# STM32MP25_CM33 register map
File version: 1.3
CPU: CM33 r0p1, little endian, MPU, FPU, vendor SysTick, 8 interrupt priority bits
Registers are 32-bit, read-write, reset 0x0 unless marked. A register's access mark holds for its fields unless they carry their own. Offsets are from the block's base; [hi:lo] are bit positions; lines under a group give offsets from that group; {n}, {i} and the like mark numbered series; 'fields as' and 'values as' point back to an identical list.

## DDRCTRL — DDRCTRL register block
Base 0x48040000
Same registers: DDRCTRL_S 0x58040000
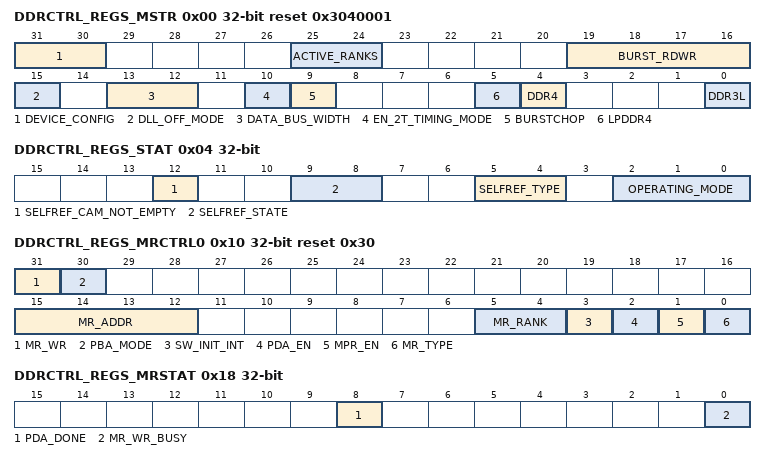
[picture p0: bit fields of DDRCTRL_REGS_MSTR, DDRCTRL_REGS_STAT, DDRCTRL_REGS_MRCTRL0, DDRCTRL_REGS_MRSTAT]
0x00 DDRCTRL_REGS_MSTR reset 0x3040001 — DDRCTRL master0 register
  [31:30] DEVICE_CONFIG — Device configuration
    0=x4 device; 1=x8 device; 2=x16 device; 3=x32 device
  [25:24] ACTIVE_RANKS — Only present for multi-rank configurations
    1=One rank; 0=Unpopulated; 3=Two ranks
  [19:16] BURST_RDWR — SDRAM burst length
    2=Burst length of 4; 4=Burst length of 8; 8=Burst length of 16 (only supported for LPDDR4)
  [15] DLL_OFF_MODE — Note: Programming mode: Quasi-dynamic Group 2.
    1=When the DDRCTRL and DRAM has to be put in DLL-off mode for low frequency operation; 0=To put DDRCTRL and DRAM in DLL-on mode for normal frequency operation
  [13:12] DATA_BUS_WIDTH — Proportion of DQ bus width that is used by the SDRAM
    0=32 bits; 1=16 bits; 2=8 bits (supported for DDR3L half populated)
  [10] EN_2T_TIMING_MODE — In 2T timing, all command signals (except chip select) are held for two clocks on the SDRAM bus.
    0=DDRCTRL uses 1T timing; 1=DDRCTRL uses 2T timing
  [9] BURSTCHOP — Burst chop (BC4 or 8 on-the-fly) enable in DDR3L/DDR4
  [5] LPDDR4 — Selects LPDDR4 SDRAM
    1=LPDDR4 SDRAM device; 0=Non-LPDDR4 device
  [4] DDR4 — Selects DDR4 SDRAM
    1=DDR4 SDRAM device; 0=Non-DDR4 device
  [0] DDR3L — Selects DDR3L SDRAM
    1=DDR3L SDRAM device; 0=Non-DDR3L SDRAM device
0x04 DDRCTRL_REGS_STAT ro — DDRCTRL operating mode status register
  [12] SELFREF_CAM_NOT_EMPTY — Self-refresh (SR) with CAMs not empty
  [9:8] SELFREF_STATE — SR or SRPD (SR power-down) for LPDDR4
    0=SDRAM not in SR; 1=SR 1; 2=SRPD; 3=SR 2
  [5:4] SELFREF_TYPE — Flags if SR (except LPDDR4), or SRPD (LPDDR4) is entered, and if it is under automatic SR control only or not
    0=SDRAM is not in SR (except LPDDR4) or SRPD (LPDDR4); 3=SDRAM is in SR (except LPDDR4) or SRPD(LPDDR4), which was caused by automatic SR only; 2=SDRAM is in SR (except LPDDR4) or SRPD (LPDDR4), which was not caused solely under automatic SR control; 1=SDRAM is in SR, which is caused by PHY master request
  [2:0] OPERATING_MODE — DDR3L design:
    0=Init; 1=Normal; 2=PDN; 3=SR/SRSRPD
0x10 DDRCTRL_REGS_MRCTRL0 reset 0x30 — DDRCTRL mode read/write control 0 register
  [31] MR_WR — Mode register (MR) read or write
  [30] PBA_MODE — PBA access execution
    0=PDA; 1=PBA
  [15:12] MR_ADDR ro — MR address to be written to
    {v}=MR{v} (v=0..7)
  [5:4] MR_RANK — Rank accessed by MR_WR in this register
    1=Select rank 0 only; 2=Select rank 1 only; 3=Select ranks 0 and 1
  [3] SW_INIT_INT — Software intervention enable
    0=Software intervention not allowed; 1=Software intervention allowed
  [2] PDA_EN — Mode register operation is MRS in PDA mode or not
    0=MRS; 1=MRS in PDA
  [1] MPR_EN — Mode register operation is MRS or WR/RD for MPR (only supported for DDR4)
    0=MRS; 1=WR/RD for MPR
  [0] MR_TYPE — Mode register operation is read or write (only for LPDDR4/DDR4)
    0=Write; 1=Read
0x14 DDRCTRL_REGS_MRCTRL1 — DDRCTRL mode read/write control 1 register
  [17:0] MR_DATA — Mode register write data for all non-LPDDR4 modes
0x18 DDRCTRL_REGS_MRSTAT ro — DDRCTRL mode register read/write status register
  [8] PDA_DONE — Initiate an MR write operation in PDA/PBA mode only if this bit is low
    0=Mode register write operation related to PDA/PBA is in progress or has not started yet; 1=Mode register write operation related to PDA/PBA has competed
  [0] MR_WR_BUSY — Initiate an MR write operation only if this bit is low
    0=The device can initiate a mode register write operation; 1=Mode register write operation is in progress
0x1C DDRCTRL_REGS_MRCTRL2 — DDRCTRL mode register read/write control 2 register
  [31:0] MR_DEVICE_SEL — Device selection during the MRS that happens in PDA mode
    1=MRS command must be applied to that device; 0=MRS commands must be skipped for that device
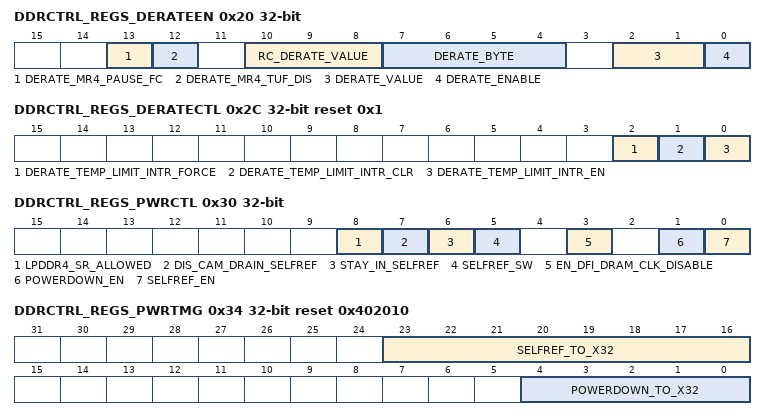
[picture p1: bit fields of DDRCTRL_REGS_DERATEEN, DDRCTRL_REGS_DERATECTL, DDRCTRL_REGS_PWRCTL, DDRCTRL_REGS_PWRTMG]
0x20 DDRCTRL_REGS_DERATEEN — DDRCTRL temperature derate enable register
  [13] DERATE_MR4_PAUSE_FC — Pauses MR4 reads
  [12] DERATE_MR4_TUF_DIS — Disables use of MR4 TUF flag (MR4[7])
    0=Use MR4 TUF flag (MR4[7]); 1=Do not use MR4 TUF Flag (MR4[7])
  [10:8] RC_DERATE_VALUE — Derate value of tless thansub>RCless than/sub> for LPDDR4
    {v}=Derating uses +{v+1} (v=0..7)
  [7:4] DERATE_BYTE — MRR data used for derating
  [2:1] DERATE_VALUE
    {v}=Derating uses +{v+1} (v=0..3)
  [0] DERATE_ENABLE — Enables derating
    0=Timing parameter derating is disabled; 1=Timing parameter derating is enabled using MR4 read value
0x24 DDRCTRL_REGS_DERATEINT reset 0x800000 — DDRCTRL temperature derate interval register
  [31:0] MR4_READ_INTERVAL — Interval between two MR4 reads
0x2C DDRCTRL_REGS_DERATECTL reset 0x1 — DDRCTRL temperature derate control register
  [2] DERATE_TEMP_LIMIT_INTR_FORCE — Interrupt force bit for DERATE_TEMP_LIMIT_INTR
  [1] DERATE_TEMP_LIMIT_INTR_CLR — Interrupt clear bit for DERATE_TEMP_LIMIT_INTR
  [0] DERATE_TEMP_LIMIT_INTR_EN — Interrupt enable bit for DERATE_TEMP_LIMIT_INTR
    1=Enabled; 0=Disabled
0x30 DDRCTRL_REGS_PWRCTL — DDRCTRL low-power control register
  [8] LPDDR4_SR_ALLOWED — Transition from SRPD to SR, and back to SRPD allowed
    0=SRPD -> SR -> SRPD not allowed; 1=SRPD -> SR -> SRPD allowed
  [7] DIS_CAM_DRAIN_SELFREF — Skipping CAM draining allowed when entering SR
    0=CAMs must be empty before entering SR; 1=CAMs are not empty before entering SR (not supported)
  [6] STAY_IN_SELFREF — SR state transition
    1=Transition from SR not allowed; 0=Transition from SR allowed
  [5] SELFREF_SW — SR state entry
    1=Software entry to SR; 0=Software exit from SR
  [3] EN_DFI_DRAM_CLK_DISABLE — dfi_dram_clk_disable enable
    0=dfi_dram_clk_disable is never asserted; 1=Assertion of dfi_dram_clk_disable as follows: In DDR3L and DDR4, can only be asserted in SR
  [1] POWERDOWN_EN — PDN enable
  [0] SELFREF_EN — SDRAM into SR enable
0x34 DDRCTRL_REGS_PWRTMG reset 0x402010 — DDRCTRL low-power timing register
  [23:16] SELFREF_TO_X32 — Maximum idle clocks before SR
  [4:0] POWERDOWN_TO_X32 — Maximum idle clocks before PDN
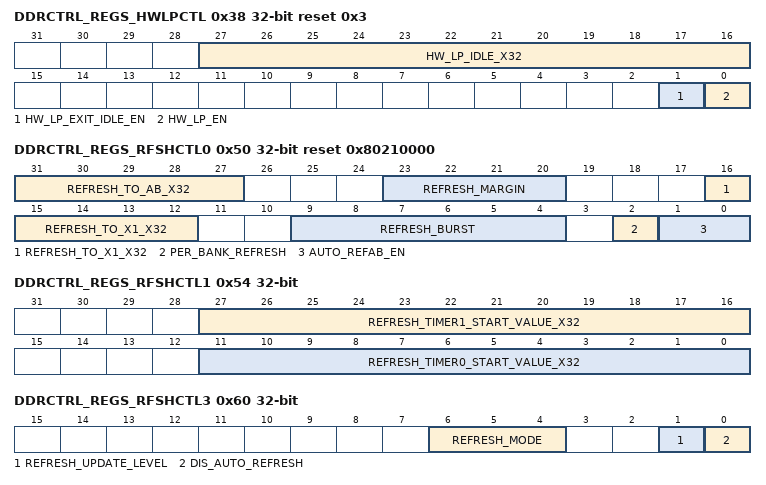
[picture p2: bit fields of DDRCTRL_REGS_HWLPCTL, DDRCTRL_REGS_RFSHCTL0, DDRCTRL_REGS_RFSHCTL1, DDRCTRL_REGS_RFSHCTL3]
0x38 DDRCTRL_REGS_HWLPCTL reset 0x3 — DDRCTRL hardware low-power control register
  [27:16] HW_LP_IDLE_X32 — Hardware idle period
  [1] HW_LP_EXIT_IDLE_EN — CACTIVE_IN_DDRC pin enable
  [0] HW_LP_EN — Hardware low-power interface enable
0x50 DDRCTRL_REGS_RFSHCTL0 reset 0x80210000 — DDRCTRL refresh control 0 register
  [31:27] REFRESH_TO_AB_X32 — When the DDRCTRL switches automatically from per-bank to all-bank refresh (if enabled by AUTO_REFAB_EN[1:0]), it will use this register to determine when to perform speculative all-bank refreshes.
  [23:20] REFRESH_MARGIN — DFI clock cycles before the critical refresh or page timer expires
  [16:12] REFRESH_TO_X1_X32 — If the refresh timer (tless thansub>RFCnomless than/sub>, also known as tless thansub>REFIless than/sub>) has expired at least once, a speculative refresh can be performed.
  [9:4] REFRESH_BURST — This bit field + 1 is the number of refresh timeouts that can be accumulated before traffic is blocked, and refreshes are forced to execute.
    0=Single refresh; 1=Burst-of-2 refresh; 7=Burst-of-8 refresh
  [2] PER_BANK_REFRESH — Per bank refresh allows traffic to flow to other banks (supported by all LPDDR4 devices).
    1=Per bank refresh; 0=All bank refresh
  [1:0] AUTO_REFAB_EN — Enables automatic switching from per-bank to all-bank refresh when the derated refresh period is small.
    0=Disable automatic switching; 1=Enable automatic switching when the derated refresh period is tless thansub>REFIless than/sub>/2 or lower; 2=Enable automatic switching when the derated refresh period is tless thansub>REFIless than/sub>/4
0x54 DDRCTRL_REGS_RFSHCTL1 — DDRCTRL refresh control 1 register
  [27:16] REFRESH_TIMER1_START_VALUE_X32 — Refresh timer start for rank 1 (only present in multirank configurations)
  [11:0] REFRESH_TIMER0_START_VALUE_X32 — Refresh timer start for rank 0 (only present in multirank configurations)
0x60 DDRCTRL_REGS_RFSHCTL3 — DDRCTRL refresh control 3 register
  [6:4] REFRESH_MODE — Fine granularity refresh mode
    0=Fixed 1x (normal mode); 1=Fixed 2x; 2=Fixed 4x; 5=Enable on-the-fly 2x (not supported); 6=Enable on-the-fly 4x (not supported)
  [1] REFRESH_UPDATE_LEVEL — Refresh register update
  [0] DIS_AUTO_REFRESH — Auto-refresh disable
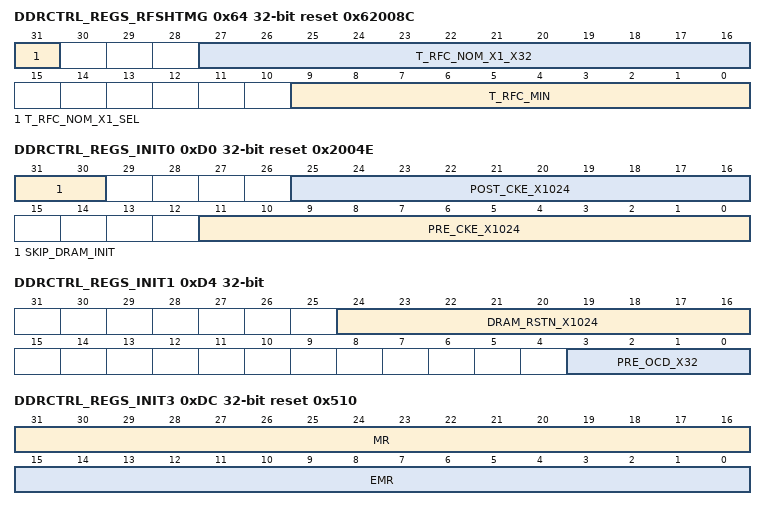
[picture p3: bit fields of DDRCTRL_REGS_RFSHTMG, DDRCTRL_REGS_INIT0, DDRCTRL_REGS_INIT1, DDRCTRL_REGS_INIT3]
0x64 DDRCTRL_REGS_RFSHTMG reset 0x62008C — DDRCTRL refresh timing register
  [31] T_RFC_NOM_X1_SEL — This bit specifies whether values of T_RFC_NOM_X1_X32 in this register and REFRESH_TO_X1_X32 in DDRCTRL_REGS_RFSHCTL0 are x1 or x32.
    0=x32 register values; 1=x1 register values
  [27:16] T_RFC_NOM_X1_X32 — Average time interval between refreshes per rank
  [9:0] T_RFC_MIN — tless thansub>RFCminless than/sub>, minimum time from refresh to refresh or activate
0x68 DDRCTRL_REGS_RFSHTMG1 reset 0x8C0000 — DDRCTRL refresh timing1 register
  [23:16] T_PBR2PBR — tless thansub>pbR2pbRless than/sub> for LPDDR4
0xD0 DDRCTRL_REGS_INIT0 reset 0x2004E — DDRCTRL SDRAM initialization 0 register
  [31:30] SKIP_DRAM_INIT — SDRAM initialization routine
    0=The SDRAM initialization routine is run after power-up; 1=The SDRAM initialization routine is skipped after power-up; 3=The SDRAM initialization routine is skipped after power-up
  [25:16] POST_CKE_X1024 — Number of cycles to wait after driving CKE high to start the SDRAM initialization sequence
  [11:0] PRE_CKE_X1024 — Number of cycles to wait after reset before driving CKE high to start the SDRAM initialization sequence
0xD4 DDRCTRL_REGS_INIT1 — DDRCTRL SDRAM initialization 1 register
  [24:16] DRAM_RSTN_X1024 — Number of cycles to assert SDRAM reset signal during
  [3:0] PRE_OCD_X32 — Wait period before driving the OCD complete command to SDRAM
0xDC DDRCTRL_REGS_INIT3 reset 0x510 — DDRCTRL SDRAM initialization 3 register
  [31:16] MR — DDR3L/DDR4: Value loaded into MR0 register
  [15:0] EMR — DDR3L/DDR4: Value to write to MR1 register (set bit 7 to 0)
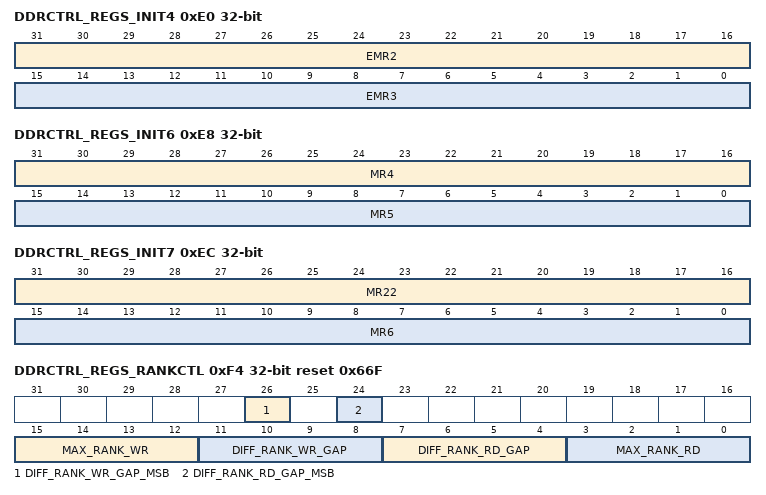
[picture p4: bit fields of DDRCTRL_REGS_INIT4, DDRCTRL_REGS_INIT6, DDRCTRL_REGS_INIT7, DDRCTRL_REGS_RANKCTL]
0xE0 DDRCTRL_REGS_INIT4 — DDRCTRL SDRAM initialization 4 register
  [31:16] EMR2 — DDR3L/DDR4: Value to write to MR2 register
  [15:0] EMR3 — DDR3L/DDR4: Value to write to MR3 register
0xE4 DDRCTRL_REGS_INIT5 reset 0x100004 — DDRCTRL SDRAM initialization 5 register
  [23:16] DEV_ZQINIT_X32 — tless thansub>ZQINITless than/sub>, ZQ initial calibration
0xE8 DDRCTRL_REGS_INIT6 — DDRCTRL SDRAM initialization 6 register
  [31:16] MR4 — DDR4: Value to be loaded into SDRAM MR4 registers
  [15:0] MR5 — DDR4: Value to be loaded into SDRAM MR5 registers
0xEC DDRCTRL_REGS_INIT7 — DDRCTRL SDRAM initialization 7 register
  [31:16] MR22 — LPDDR4: Value to be loaded into SDRAM MR22 registers
  [15:0] MR6 — DDR4: Value to be loaded into SDRAM MR6 registers
0xF4 DDRCTRL_REGS_RANKCTL reset 0x66F — DDRCTRL rank control register
  [26] DIFF_RANK_WR_GAP_MSB — 1-bit extension to be used when DIFF_RANK_WR_GAP in this register needs to be set
  [24] DIFF_RANK_RD_GAP_MSB — 1-bit extension to be used when DIFF_RANK_RD_GAP in this register needs to be set
  [15:12] MAX_RANK_WR — Maximum number of writes that can be scheduled consecutively
  [11:8] DIFF_RANK_WR_GAP — Number of clocks of gap in data responses when performing consecutive writes to different ranks (only present for multirank configurations)
  [7:4] DIFF_RANK_RD_GAP — Number of clocks of gap in data responses when performing consecutive reads to different ranks (only present for multi-rank configurations)
  [3:0] MAX_RANK_RD — Maximum number of reads that can be scheduled consecutively
0xF8 DDRCTRL_REGS_RANKCTL1 reset 0x8 — Rank control 1 register
  [5:0] WR2RD_DR — Minimum time from write command to read command on different physical ranks.
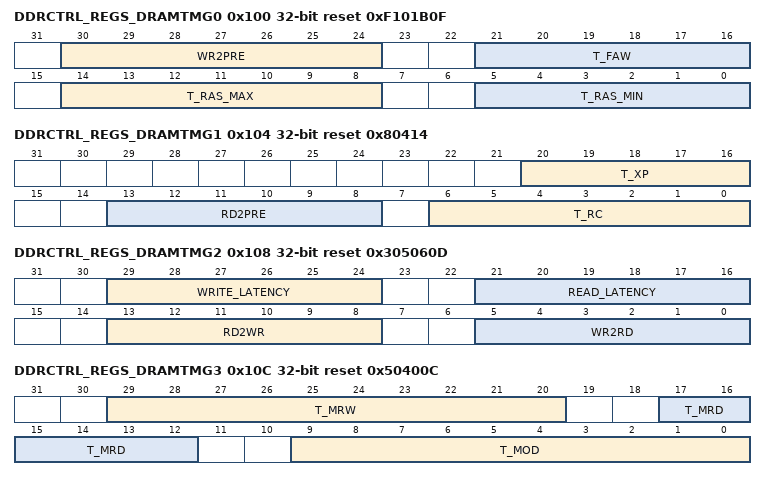
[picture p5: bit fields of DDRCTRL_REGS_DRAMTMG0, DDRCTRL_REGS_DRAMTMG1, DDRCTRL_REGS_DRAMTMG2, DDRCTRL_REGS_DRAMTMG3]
0x100 DDRCTRL_REGS_DRAMTMG0 reset 0xF101B0F — DDRCTRL SDRAM timing 0 register
  [30:24] WR2PRE — Minimum time between write and precharge to same bank
  [21:16] T_FAW — tless thansub>FAWless than/sub>, valid only when 8 or more banks (or banks x bank groups) are present
  [14:8] T_RAS_MAX — tless thansub>RASmaxless than/sub>, max time between activate and precharge to same bank
  [5:0] T_RAS_MIN — tless thansub>RASminless than/sub>, minimum time between activate and precharge to same bank
0x104 DDRCTRL_REGS_DRAMTMG1 reset 0x80414 — DDRCTRL SDRAM timing 1 register
  [20:16] T_XP — tless thansub>XPless than/sub>, minimum time after PDN exit to any operation
  [13:8] RD2PRE — tless thansub>RTPless than/sub>, minimum time from read to precharge of same bank
  [6:0] T_RC — tless thansub>RCless than/sub>, minimum time between activates to same bank
0x108 DDRCTRL_REGS_DRAMTMG2 reset 0x305060D — DDRCTRL SDRAM timing 2 register
  [29:24] WRITE_LATENCY — Time from write command to write data on SDRAM interface
  [21:16] READ_LATENCY — Time from read command to read data on SDRAM interface
  [13:8] RD2WR — Minimum time from read command to write command
  [5:0] WR2RD — In DDR4, minimum time from write command to read command for same bank group.
0x10C DDRCTRL_REGS_DRAMTMG3 reset 0x50400C — DDRCTRL SDRAM timing 3 register
  [29:20] T_MRW — Time to wait after a mode register write or read (MRW or MRR)
  [17:12] T_MRD — tless thansub>MRDless than/sub>, number of cycles to wait after a mode register write or read
  [9:0] T_MOD — tless thansub>MODless than/sub>, number of cycles between load mode command and following non-load mode command (only in DDR3L and DDR4)
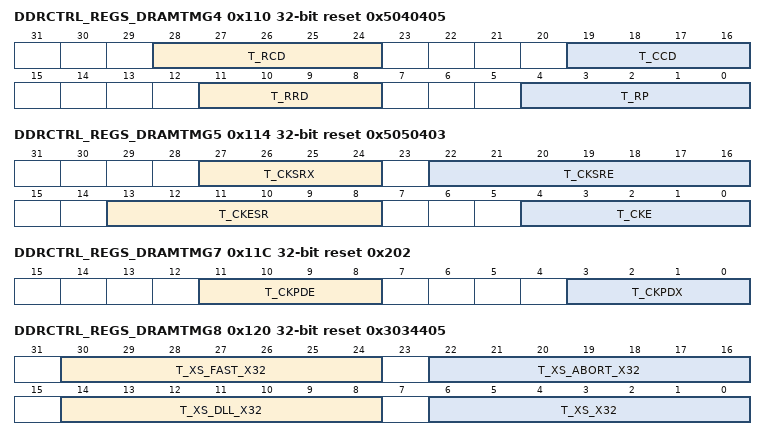
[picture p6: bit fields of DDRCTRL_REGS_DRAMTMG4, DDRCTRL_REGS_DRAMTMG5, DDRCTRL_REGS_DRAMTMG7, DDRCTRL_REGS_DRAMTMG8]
0x110 DDRCTRL_REGS_DRAMTMG4 reset 0x5040405 — DDRCTRL SDRAM timing 4 register
  [28:24] T_RCD — tless thansub>RCDless than/sub> - tless thansub>ALless than/sub>, minimum time from activate to read or write command to same bank
  [19:16] T_CCD — For DDR4, tless thansub>CCD_Lless than/sub>, minimum time between two reads or two writes for same bank group.
  [11:8] T_RRD — For DDR4, tless thansub>RRD_Lless than/sub>, minimum time between activates from bank a to bank b for same bank.
  [4:0] T_RP — tless thansub>RPless than/sub>, minimum time from single-bank precharge to activate of same bank
0x114 DDRCTRL_REGS_DRAMTMG5 reset 0x5050403 — DDRCTRL SDRAM timing 5 register
  [27:24] T_CKSRX — Time before SR exit that CK is maintained as a valid clock before issuing SRX
  [22:16] T_CKSRE — Time after SR entry that CK is maintained as a valid clock
  [13:8] T_CKESR — Minimum CKE low width for SR or SRPD entry to exit timing
  [4:0] T_CKE — Minimum number of cycles of CKE high/low during PDN and SR
0x118 DDRCTRL_REGS_DRAMTMG6 reset 0x2020005 — DDRCTRL SDRAM timing 6 register
  [3:0] T_CKCSX — time before clock Stop exit that CK is maintained as a valid clock before issuing clock Stop exit
0x11C DDRCTRL_REGS_DRAMTMG7 reset 0x202 — DDRCTRL SDRAM timing 7 register
  [11:8] T_CKPDE — Time after PDN entry that CK is maintained as a valid clock
  [3:0] T_CKPDX — Time before PDN exit that CK is maintained as a valid clock
0x120 DDRCTRL_REGS_DRAMTMG8 reset 0x3034405 — DDRCTRL SDRAM timing 8 register
  [30:24] T_XS_FAST_X32 — tless thansub>XS_FASTless than/sub>, exit SR to ZQCL, ZQCS and MRS (only CL, WR, RTP mode)
  [22:16] T_XS_ABORT_X32 — tless thansub>XS_ABORTless than/sub>, exit SR to commands not requiring a locked DLL
  [14:8] T_XS_DLL_X32 — tless thansub>XSDLLless than/sub>, exit SR to commands requiring a locked DLL (only for DDR3L and DDR4 SDRAMs)
  [6:0] T_XS_X32 — tless thansub>XSless than/sub>, exit SR to commands not requiring a locked DLL (only for DDR3L and DDR4 SDRAMs)
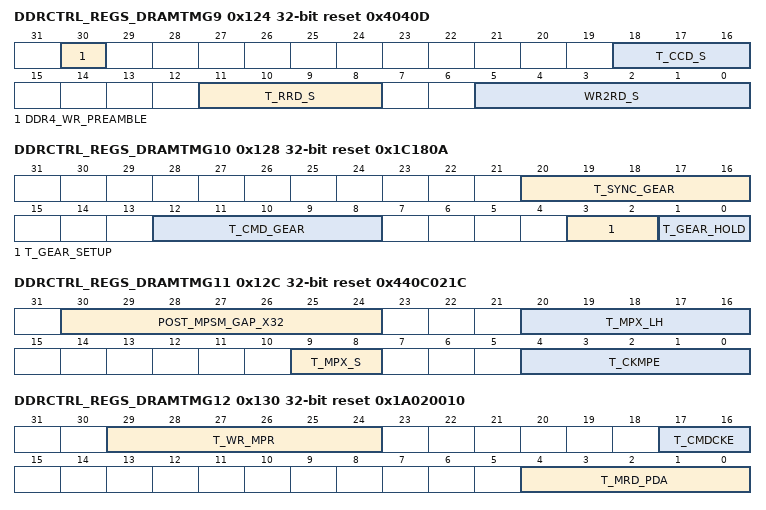
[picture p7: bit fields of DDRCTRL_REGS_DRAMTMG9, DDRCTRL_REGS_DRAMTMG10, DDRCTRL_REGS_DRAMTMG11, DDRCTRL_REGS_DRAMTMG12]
0x124 DDRCTRL_REGS_DRAMTMG9 reset 0x4040D — DDRCTRL SDRAM timing 9 register
  [30] DDR4_WR_PREAMBLE — DDR4 write preamble mode
    0=1tless thansub>CKless than/sub> preamble; 1=2tless thansub>CKless than/sub> preamble
  [18:16] T_CCD_S — tless thansub>CCD_Sless than/sub>, minimum time between two reads/writes for different bank group
  [11:8] T_RRD_S — tless thansub>RRD_Sless than/sub>, minimum time between activates for different bank group
  [5:0] WR2RD_S — Minimum time from write command to read command for different bank group
0x128 DDRCTRL_REGS_DRAMTMG10 reset 0x1C180A — DDRCTRL SDRAM timing 10 register
  [20:16] T_SYNC_GEAR — Time between MRS command and the sync pulse time
  [12:8] T_CMD_GEAR — sync pulse to first valid command
  [3:2] T_GEAR_SETUP — Geardown setup time
  [1:0] T_GEAR_HOLD — Geardown hold time
0x12C DDRCTRL_REGS_DRAMTMG11 reset 0x440C021C — DDRCTRL SDRAM timing 11 register
  [30:24] POST_MPSM_GAP_X32 — tless thansub>XMPDLLless than/sub>, minimum exit MPSM to commands requiring
  [20:16] T_MPX_LH — tless thansub>MPX_LHless than/sub>, minimum CS_n low hold time to CKE rising edge
  [9:8] T_MPX_S — tless thansub>MPX_Sless than/sub>, minimum time CS setup time to CKE
  [4:0] T_CKMPE — tless thansub>CKMPEless than/sub>, minimum valid clock requirement after MPSM entry
0x130 DDRCTRL_REGS_DRAMTMG12 reset 0x1A020010 — DDRCTRL SDRAM timing 12 register
  [29:24] T_WR_MPR — Cycles between MPR write and other commands (DDR4 only)
  [17:16] T_CMDCKE — tless thansub>CMDCKEless than/sub>, delay from valid command to CKE input low
  [4:0] T_MRD_PDA — tless thansub>MRD_PDAless than/sub>, cycle time of mode register set command in PDA mode
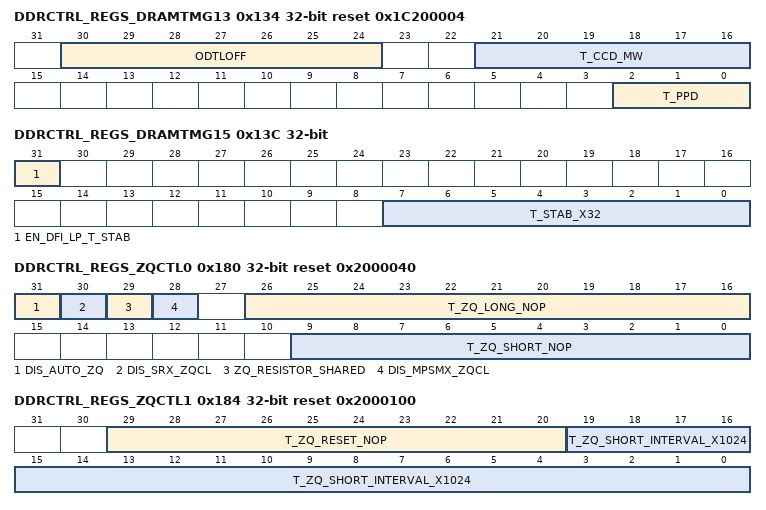
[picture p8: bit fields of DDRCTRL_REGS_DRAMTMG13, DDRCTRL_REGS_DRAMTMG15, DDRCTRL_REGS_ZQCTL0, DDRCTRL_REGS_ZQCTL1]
0x134 DDRCTRL_REGS_DRAMTMG13 reset 0x1C200004 — DDRCTRL SDRAM timing 13 register
  [30:24] ODTLOFF — ODTLoff, latency from CAS-2 command to ODToff reference (only LPDDR4)
  [21:16] T_CCD_MW — tless thansub>CCDMWless than/sub>, minimum time from write or masked write to masked write command for same bank (only LPDDR4)
  [2:0] T_PPD — tless thansub>PPDless than/sub>, minimum time from precharge to precharge command (only LPDDR4)
0x138 DDRCTRL_REGS_DRAMTMG14 reset 0xA0 — DDRCTRL SDRAM timing 14 register
  [11:0] T_XSR — tless thansub>XSRless than/sub>, exit SR time to any command (only LPDDR4)
0x13C DDRCTRL_REGS_DRAMTMG15 — DDRCTRL SDRAM timing 15 register
  [31] EN_DFI_LP_T_STAB — Note: Programming mode: Quasi-dynamic Group 2, Group 4.
    1=Enable using tless thansub>STABless than/sub> when exiting DFI LP; 0=Disable using tless thansub>STABless than/sub> when exiting DFI LP
  [7:0] T_STAB_X32 — tless thansub>STABless than/sub>, stabilization time
0x180 DDRCTRL_REGS_ZQCTL0 reset 0x2000040 — DDRCTRL ZQ control 0 register
  [31] DIS_AUTO_ZQ — Note: Programming mode: Dynamic.
    1=Disable DDRCTRL generation of ZQCS/MPC(ZQ calibration) command; 0=Internally generate ZQCS/MPC (ZQ calibration) commands based on T_ZQ_SHORT_INTERVAL_X1024 in DDRCTRL_REGS_ZQCTL1
  [30] DIS_SRX_ZQCL — Note: Programming mode: Quasi-dynamic Group 2, Group 4.
    1=Disable issuing a ZQCL/MPC(ZQ calibration) command at SR or SRPD exit; 0=Enable issuing a ZQCL/MPC(ZQ calibration) command at SR or SRPD exit
  [29] ZQ_RESISTOR_SHARED — ZQinit/ZQCL/ZQCS/MPC(ZQ calibration) commands are sent to one rank at a time with tless thansub>ZQinitless than/sub>, tless thansub>ZQCLless than/sub>, tless thansub>ZQCSless than/sub>, tless thansub>ZQCALless than/sub>, and tless thansub>ZQLATless than/sub> met between commands (so that commands to different ranks do not overlap).
    1=Denotes that ZQ resistor is shared between ranks; 0=ZQ resistor is not shared
  [28] DIS_MPSMX_ZQCL — Only for DDR4
    1=Disable issuing a ZQCL command at MPS (maximum power saving) mode exit; 0=Enable issuing a ZQCL command at MPS mode exit
  [26:16] T_ZQ_LONG_NOP — DFI clock cycles of NOP required after ZQCL (ZQcalibration long)
  [9:0] T_ZQ_SHORT_NOP — DFI clock cycles of NOP required after ZQCS (ZQ calibration short)
0x184 DDRCTRL_REGS_ZQCTL1 reset 0x2000100 — DDRCTRL ZQ control 1 register
  [29:20] T_ZQ_RESET_NOP — tless thansub>ZQResetless than/sub>, DFI clock cycles of NOP required after ZQReset
  [19:0] T_ZQ_SHORT_INTERVAL_X1024 — Average interval to wait between automatically issuing ZQCS (ZQ calibration short) and MPC(ZQ calibration) commands
0x188 DDRCTRL_REGS_ZQCTL2 — DDRCTRL ZQ control 2 register
  [0] ZQ_RESET — ZQ Reset operation
0x18C DDRCTRL_REGS_ZQSTAT ro — DDRCTRL ZQ status register
  [0] ZQ_RESET_BUSY — ZQ Reset operation possible only if this bit is low
    0=AZQ Reset operation can be initiated; 1=A ZQ Reset operation is in progress
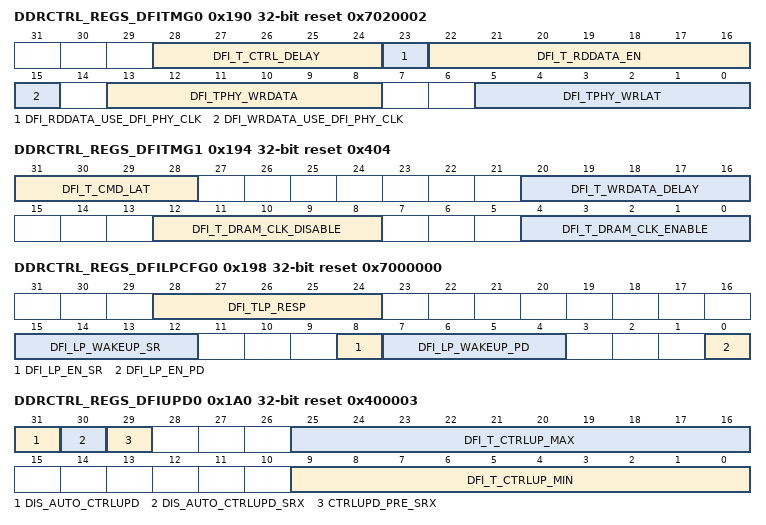
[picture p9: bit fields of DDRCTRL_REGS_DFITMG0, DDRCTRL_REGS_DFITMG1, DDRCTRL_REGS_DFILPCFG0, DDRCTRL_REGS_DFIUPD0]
0x190 DDRCTRL_REGS_DFITMG0 reset 0x7020002 — DDRCTRL DFI timing 0 register
  [28:24] DFI_T_CTRL_DELAY — DFI clock cycles after an assertion or deassertion
  [23] DFI_RDDATA_USE_DFI_PHY_CLK — dfi_rddata_en, dfi_rddata, or dfi_rddata_valid generated
    0=HDR (DFI clock) cycles; 1=SDR (DFI PHY clock) cycles
  [22:16] DFI_T_RDDATA_EN — Time from the assertion of a read command on the DFI interface
  [15] DFI_WRDATA_USE_DFI_PHY_CLK — dfi_wrdata_en, dfi_wrdata, or dfi_wrdata_mask generated
    0=HDR (DFI clock) cycles; 1=SDR (DFI PHY clock) cycles
  [13:8] DFI_TPHY_WRDATA — tless thansub>PHY_WRDATA, less than/sub>number of clock cycles between dfi_wrdata_en assertion and associated write data driven on dfi_wrdata
  [5:0] DFI_TPHY_WRLAT — tless thansub>PHY_WRLATless than/sub>, write latency
0x194 DDRCTRL_REGS_DFITMG1 reset 0x404 — DDRCTRL DFI timing 1 register
  [31:28] DFI_T_CMD_LAT — Number of DFI PHY clock cycles between when dfi_cs assertion and when the associated command is driven
  [20:16] DFI_T_WRDATA_DELAY — tless thansub>WRDATA_DELAYless than/sub>, DFI clock cycles between dfi_wrdata_en assertion, and when the corresponding write data transfer is completed on the DRAM bus
  [12:8] DFI_T_DRAM_CLK_DISABLE — DFI clock cycles from dfi_dram_clk_disable assertion on the DFI until the clock to the DRAM memory devices, at the PHY-DRAM boundary
  [4:0] DFI_T_DRAM_CLK_ENABLE — DFI clock cycles from dfi_dram_clk_disable deassertion on the DFI until the first valid rising edge of the clock to the DRAM memory devices,
0x198 DDRCTRL_REGS_DFILPCFG0 reset 0x7000000 — DDRCTRL DFI low-power configuration 0 register
  [28:24] DFI_TLP_RESP — tless thansub>LP_RESPless than/sub>, DFI clock cycles setting for DFI
  [15:12] DFI_LP_WAKEUP_SR — tless thansub>LP_WAKEUPless than/sub>, DFI clock cycles to drive on dfi_lp_wakeup signal
    0=16 cycles; 1=32 cycles; 2=64 cycles; 3=128 cycles; 4=256 cycles; 5=512 cycles; 6=1024 cycles; 7=2048 cycles; 8=4096 cycles; 9=8192 cycles; 10=16384 cycles; 11=32768 cycles; 12=65536 cycles; 13=131072 cycles; 14=262144 cycles; 15=Unlimited
  [8] DFI_LP_EN_SR — DFI low-power interface handshaking during SR entry/exit
    0=Disabled; 1=Enabled
  [7:4] DFI_LP_WAKEUP_PD — tless thansub>LP_WAKEUPless than/sub>, DFI clock cycles to drive on dfi_lp_wakeup signal when PDN is entered
    values as DFI_LP_WAKEUP_SR
  [0] DFI_LP_EN_PD — DFI low-power interface handshaking during PDN entry/exit
    0=Disabled; 1=Enabled
0x1A0 DDRCTRL_REGS_DFIUPD0 reset 0x400003 — DDRCTRL DFI update 0 register
  [31] DIS_AUTO_CTRLUPD — Note: Programming mode: Quasi-dynamic Group 3.
    1=Disable the automatic DFI_CTRLUPD_REQ generation; 0=DDRCTRL issues DFI_CTRLUPD_REQ periodically
  [30] DIS_AUTO_CTRLUPD_SRX — Note: Programming mode: Static.
    1=Disable the automatic DFI_CTRLUPD_REQ generation by the DDRCTRL at SR exit; 0=DDRCTRL issues a DFI_CTRLUPD_REQ before or after exiting SR, depending on CTRLUPD_PRE_SRX in this register
  [29] CTRLUPD_PRE_SRX — DFI_CTRLUPD_REQ requirements at SRX
    0=Send DFI_CTRLUPD_REQ after SRX; 1=Send DFI_CTRLUPD_REQ before SRX
  [25:16] DFI_T_CTRLUP_MAX — Maximum number of DFI clock cycles that
  [9:0] DFI_T_CTRLUP_MIN — Minimum number of DFI clock cycles to which
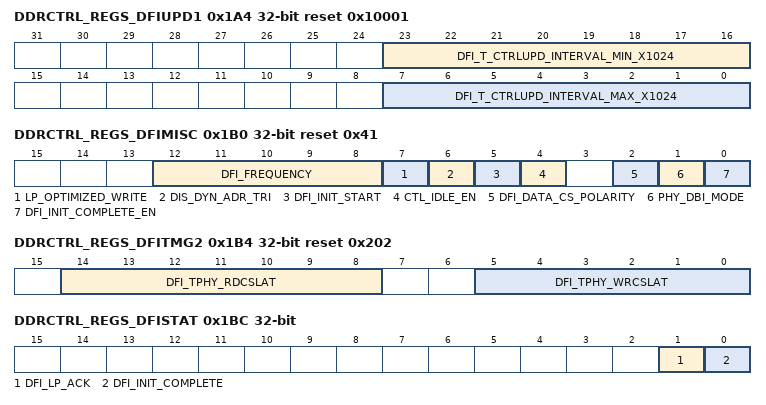
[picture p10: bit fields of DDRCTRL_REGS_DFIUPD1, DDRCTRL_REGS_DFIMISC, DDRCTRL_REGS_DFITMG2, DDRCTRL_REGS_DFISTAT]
0x1A4 DDRCTRL_REGS_DFIUPD1 reset 0x10001 — DDRCTRL DFI update 1 register
  [23:16] DFI_T_CTRLUPD_INTERVAL_MIN_X1024 — Minimum amount of time between DDRCTRL initiated DFI update requests (which is executed whenever the DDRCTRL is idle)
  [7:0] DFI_T_CTRLUPD_INTERVAL_MAX_X1024 — Maximum amount of time between DDRCTRL initiated DFI update requests
0x1A8 DDRCTRL_REGS_DFIUPD2 reset 0x80000000 — DDRCTRL DFI update 2 register
  [31] DFI_PHYUPD_EN — Enables the support for acknowledging PHY-initiated updates
    0=Disabled; 1=Enabled
0x1B0 DDRCTRL_REGS_DFIMISC reset 0x41 — DDRCTRL DFI miscellaneous control register
  [12:8] DFI_FREQUENCY — System operating frequency
  [7] LP_OPTIMIZED_WRITE — Note: Programming mode: Quasi-dynamic Group 3
    1=LPDDR4 write DQ is set to 0xF8 if masked write with enabling DBI; 0=LPDDR4 write DQ is set to 0xFF
  [6] DIS_DYN_ADR_TRI — the PHY can detect it to turn the command/address bus Hi-Z.
    1=PHY specific dynamic tristating is disabled (specific feature to some Synopsys PHYs); 0=A special IDLE command is issued on the DFI while dfi_cs is inactive state, so that
  [5] DFI_INIT_START — PHY init start request
  [4] CTL_IDLE_EN — Enables support of ctl_idle signal (non-DFI related pin specific to certain Synopsys PHYs)
  [2] DFI_DATA_CS_POLARITY — Polarity of dfi_wrdata_cs and dfi_rddata_cs signals
    0=Active low; 1=Active high
  [1] PHY_DBI_MODE — DBI implemented in DDRC or PHY
    0=DDRC implements DBI functionality; 1=PHY implements DBI functionality
  [0] DFI_INIT_COMPLETE_EN — PHY initialization complete enable
0x1B4 DDRCTRL_REGS_DFITMG2 reset 0x202 — DDRCTRL DFI timing 2 register
  [14:8] DFI_TPHY_RDCSLAT — tless thansub>PHY_RDCSLAT, less than/sub>DFI PHY clock cycles between read command sent on the DFI control interface, and associated dfi_rddata_cs signal asserted
  [5:0] DFI_TPHY_WRCSLAT — tless thansub>PHY_WRCSLATless than/sub>, DFI PHY clock cycles between write command sent on the DFI control interface, and associated dfi_wrdata_cs signal asserted.
0x1B8 DDRCTRL_REGS_DFITMG3 — DDRCTRL DFI timing 3 register
  [4:0] DFI_T_GEARDOWN_DELAY — Delay from dfi_geardown_en assertion to the time of t
0x1BC DDRCTRL_REGS_DFISTAT ro — DDRCTRL DFI status register
  [1] DFI_LP_ACK — Stores the value of dfi_lp_ack input to the controller
  [0] DFI_INIT_COMPLETE — Status flag that announces when DFI initialization is completed
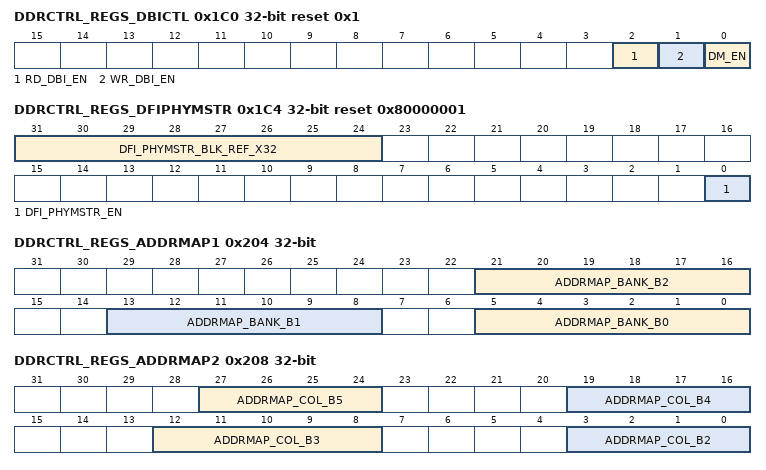
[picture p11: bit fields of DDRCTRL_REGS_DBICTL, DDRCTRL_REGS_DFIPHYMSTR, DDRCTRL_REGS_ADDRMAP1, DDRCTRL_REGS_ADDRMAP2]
0x1C0 DDRCTRL_REGS_DBICTL reset 0x1 — DDRCTRL DM/DBI control register
  [2] RD_DBI_EN — Read DBI enable signal in DDRC
    0=Read DBI disabled; 1=Read DBI enabled
  [1] WR_DBI_EN — Write DBI enable signal in DDRC
    0=Write DBI disabled; 1=Write DBI enabled
  [0] DM_EN — DM enable signal in DDRC
    0=DM disabled; 1=DM enabled
0x1C4 DDRCTRL_REGS_DFIPHYMSTR reset 0x80000001 — DDRCTRL DFI PHY master register
  [31:24] DFI_PHYMSTR_BLK_REF_X32 — Maximum number of DFI clock cycles that are needed to send pending refreshes before starting SR entry process
    0=0 DFI clock cycles (no delay); 1=32 DFI clock cycles; 255=8160 DFI clock cycles
  [0] DFI_PHYMSTR_EN — PHY master interface enable
    0=Disabled; 1=Enabled
0x200 DDRCTRL_REGS_ADDRMAP0 — DDRCTRL address map 0 register
  [4:0] ADDRMAP_CS_BIT0 — This bit field selects the HIF address bit used as rank address bit 0.
0x204 DDRCTRL_REGS_ADDRMAP1 — DDRCTRL address map 1 register
  [21:16] ADDRMAP_BANK_B2 — This bit field selects the HIF address bit used as bank address bit 2.
  [13:8] ADDRMAP_BANK_B1 — This bit field selects the HIF address bits used as bank address bit 1.
  [5:0] ADDRMAP_BANK_B0 — This bit field selects the HIF address bits used as bank address bit 0.
0x208 DDRCTRL_REGS_ADDRMAP2 — DDRCTRL address map 2 register
  [27:24] ADDRMAP_COL_B5 — Full bus width mode: selects the HIF address bit used as columnaddress bit 5.
  [19:16] ADDRMAP_COL_B4 — Full bus width mode: selects the HIF address bit used as column address bit 4.
  [12:8] ADDRMAP_COL_B3 — Full bus width mode: selects the HIF address bit used as column address bit 3.
  [3:0] ADDRMAP_COL_B2 — Full bus width mode: selects the HIF address bit used as column address bit 2.
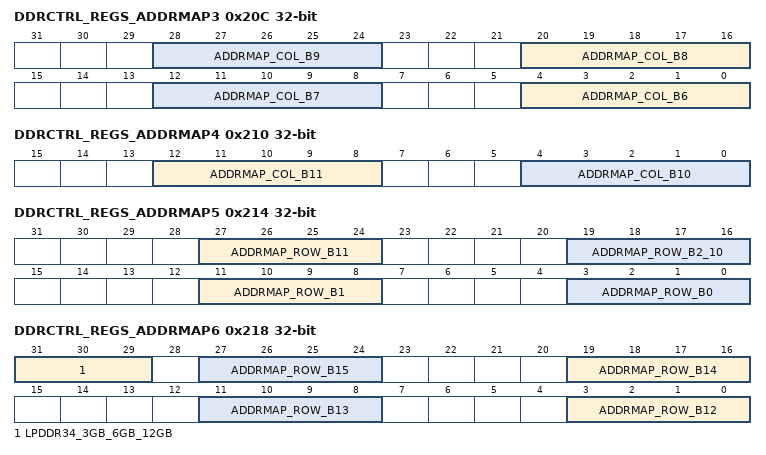
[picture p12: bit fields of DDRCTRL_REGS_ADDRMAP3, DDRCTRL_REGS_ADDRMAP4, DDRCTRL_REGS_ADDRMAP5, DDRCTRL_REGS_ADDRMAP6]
0x20C DDRCTRL_REGS_ADDRMAP3 — DDRCTRL address map 3 register
  [8n-44:8n-48] ADDRMAP_COL_B{n} (n=6..9) — Full bus width mode: selects the HIF address bit used as column address bit {n}.
0x210 DDRCTRL_REGS_ADDRMAP4 — DDRCTRL address map 4 register
  [12:8] ADDRMAP_COL_B11 — Full bus width mode: selects the HIF address bit used as column address bit 13.
  [4:0] ADDRMAP_COL_B10 — Full bus width mode: selects the HIF address bit used as column address bit 11.
0x214 DDRCTRL_REGS_ADDRMAP5 — DDRCTRL address map 5 register
  [27:24] ADDRMAP_ROW_B11 — This bit field selects the HIF address bit used as row address bit 11.
  [19:16] ADDRMAP_ROW_B2_10 — This bit field selects the HIF address bits used as row address bits 2 to 10.
  [11:8] ADDRMAP_ROW_B1 — This bit field selects the HIF address bits used as row address bit 1.
  [3:0] ADDRMAP_ROW_B0 — This bit field selects the HIF address bits used as row address bit 0.
0x218 DDRCTRL_REGS_ADDRMAP6 — DDRCTRL address map 6 register
  [31:29] LPDDR34_3GB_6GB_12GB — Density size/channel for LPDDR4 SDRAM device in use
    0=No LPDDR4 SDRAM 3-, 6, or 12-Gbyte device; 1=LPDDR4 SDRAM 3-Gbyte device with x16 mode; 2=LPDDR4 SDRAM 6-Gbyte device with x16 mode, or 3-Gbyte device with byte mode; 3=LPDDR4 SDRAM 12-Gbyte device with x16 mode, or 6-Gbyte device with byte mode; 5=LPDDR4 SDRAM 12-Gbyte device with byte mode
  [27:24] ADDRMAP_ROW_B15 — This bit field selects the HIF address bit used as row address bit 15.
  [19:16] ADDRMAP_ROW_B14 — This bit field selects the HIF address bit used as row address bit 14.
  [11:8] ADDRMAP_ROW_B13 — This bit field selects the HIF address bit used as row address bit 13.
  [3:0] ADDRMAP_ROW_B12 — This bit field selects the HIF address bit used as row address bit 12
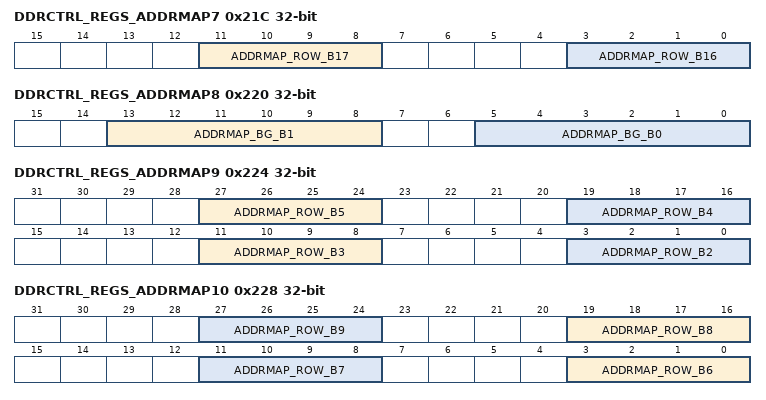
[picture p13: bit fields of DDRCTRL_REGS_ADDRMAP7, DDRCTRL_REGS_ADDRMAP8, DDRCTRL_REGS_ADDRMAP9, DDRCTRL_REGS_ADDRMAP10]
0x21C DDRCTRL_REGS_ADDRMAP7 — DDRCTRL address map 7 register
  [11:8] ADDRMAP_ROW_B17 — This bit field selects the HIF address bit used as row address bit 17.
  [3:0] ADDRMAP_ROW_B16 — This bit field selects the HIF address bit used as row address bit 16.
0x220 DDRCTRL_REGS_ADDRMAP8 — DDRCTRL address map 8 register
  [13:8] ADDRMAP_BG_B1 — This bit field selects the HIF address bits used as bank group address bit 1.
  [5:0] ADDRMAP_BG_B0 — This bit field selects the HIF address bits used as bank group address bit 0
0x224 DDRCTRL_REGS_ADDRMAP9 — DDRCTRL address map 9 register
  [27:24] ADDRMAP_ROW_B5 — This bit field selects the HIF address bits used as row address bit 5.
  [19:16] ADDRMAP_ROW_B4 — This bit field selects the HIF address bits used as row address bit 4
  [11:8] ADDRMAP_ROW_B3 — This bit field selects the HIF address bits used as row address bit 3
  [3:0] ADDRMAP_ROW_B2 — This bit field selects the HIF address bits used as row address bit 2
0x228 DDRCTRL_REGS_ADDRMAP10 — DDRCTRL address map 10 register
  [8n-45:8n-48] ADDRMAP_ROW_B{n} (n=6..9) — This bit field selects the HIF address bits used as row address bit {n}
0x22C DDRCTRL_REGS_ADDRMAP11 — DDRCTRL address map 11 register
  [3:0] ADDRMAP_ROW_B10 — This bit field selects the HIF address bits used as row address bit 10
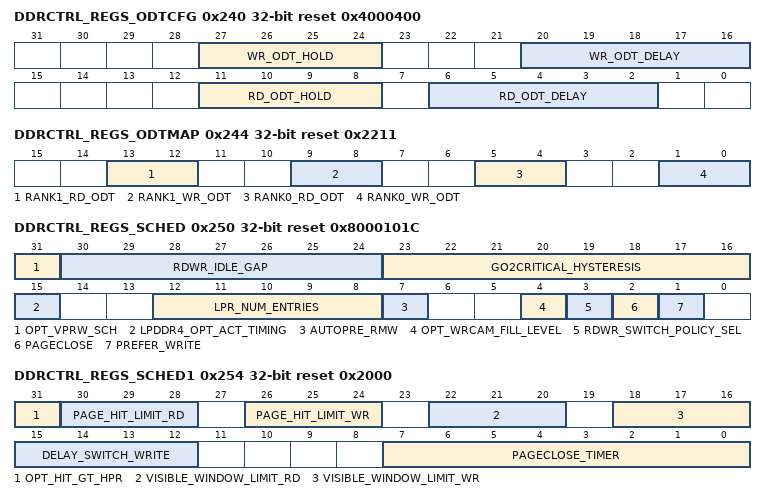
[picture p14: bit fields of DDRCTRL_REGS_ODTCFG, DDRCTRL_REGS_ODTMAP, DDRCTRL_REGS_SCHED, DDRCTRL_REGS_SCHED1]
0x240 DDRCTRL_REGS_ODTCFG reset 0x4000400 — DDRCTRL ODT configuration register
  [27:24] WR_ODT_HOLD — DFI PHY clock cycles to hold ODT for a write command
  [20:16] WR_ODT_DELAY — DFI PHY clock cycles, from issuing a write command to setting ODT values associated with this command
  [11:8] RD_ODT_HOLD — DFI PHY clock cycles to hold ODT for a read command
  [6:2] RD_ODT_DELAY — DFI PHY clock cycles, from issuing a read command to setting ODT values associated with that command
0x244 DDRCTRL_REGS_ODTMAP reset 0x2211 — DDRCTRL ODT/rank map register
  [13:12] RANK1_RD_ODT — Remote ODTs to turn on during a read from rank 1
  [9:8] RANK1_WR_ODT — Remote ODTs to turn on during a write to rank 1
  [5:4] RANK0_RD_ODT — Remote ODTs to turn on during a read from rank 0
  [1:0] RANK0_WR_ODT — Remote ODTs to turn on during a write to rank 0
0x250 DDRCTRL_REGS_SCHED reset 0x8000101C — DDRCTRL scheduler control register
  [31] OPT_VPRW_SCH — Optimize exVPR/exVPW scheduling.
    0=When any exVPR/exVPW are pending on CAM, read/write command of all other traffic class are masked to be scheduled; 1=When any exVPR/exVPW are pending as page-hit, read/write command of all other traffic class are masked to be scheduled
  [30:24] RDWR_IDLE_GAP — When the preferred transaction store is empty for these many clock cycles, switch to the alternate transaction store if it is non-empty.
    0=The transaction store switching happens immediately when the switching conditions become true
  [23:16] GO2CRITICAL_HYSTERESIS — Not used
  [15] LPDDR4_OPT_ACT_TIMING — Optimized ACT timing control for LPDDR4
    1=Enable this feature; 0=Disable this feature
  [12:8] LPR_NUM_ENTRIES — Number of entries in the low-priority transaction store
  [7] AUTOPRE_RMW — Selection of the hif_cmd_autopre behavior if a RMW is received on HIF
    1=Apply auto-precharge only for write part of RMW; 0=Apply auto-precharge for both read and write parts of RMW
  [4] OPT_WRCAM_FILL_LEVEL — Enable the feature of optimized write CAM fill level by switching to write when write CAM reaches certain fill level set in DDRCTRL_REGS_SCHED3.
    0=Disabled; 1=Enabled
  [3] RDWR_SWITCH_POLICY_SEL — Selects read write switching policy.
    1=Select 'enhanced' read write switching policy; 0=Select 'original' read write switching policy
  [2] PAGECLOSE — to this bank.
    1=The bank is kept open only while there are page hit transactions available in the CAM; 0=The bank remains open until there is a need to close it (to open a different page, or for page timeout or refresh timeout)
  [1] PREFER_WRITE — If this bit is set, the bank selector prefers writes over reads.
0x254 DDRCTRL_REGS_SCHED1 reset 0x2000 — DDRCTRL scheduler control 1 register
  [31] OPT_HIT_GT_HPR — Optimize the priority between page-hit LPR and page-miss HPR.
    0=Page-miss HPR has priority (default); 1=Page-hit LPR has priority
  [30:28] PAGE_HIT_LIMIT_RD — Page-hit limiter for read.
    0=Disable this feature; 1=4; 2=8; 3=16; 4=32
  [26:24] PAGE_HIT_LIMIT_WR — Page-hit limiter for write.
    0=Disable this feature; 1=4; 2=8; 3=16; 4=32
  [22:20] VISIBLE_WINDOW_LIMIT_RD — Visible window limiter for read.
    0=Disable this feature; 1=31; 2=63; 3=127; 4=255
  [18:16] VISIBLE_WINDOW_LIMIT_WR — Visible window limiter for write.
    0=Disable this feature; 1=31; 2=63; 3=127; 4=255
  [15:12] DELAY_SWITCH_WRITE — Indicates the number of cycles to delay switching read to write mode when write page-hit request is there and no read page-hit request is there.
    0=no delay; 1=2 cycles delay
  [7:0] PAGECLOSE_TIMER — This bit field works in conjunction with PAGECLOSE in DDRCTRL_REGS_SCHED.
    0=An auto-precharge can be scheduled for last read or write command in the CAM
0x25C DDRCTRL_REGS_PERFHPR1 reset 0xF000001 — DDRCTRL high priority read CAM 1 register
  [31:24] HPR_XACT_RUN_LENGTH — Transactions serviced once HPR queue goes critical
  [15:0] HPR_MAX_STARVE — DFI clocks that HPR queue can be starved before it goes critical
0x264 DDRCTRL_REGS_PERFLPR1 reset 0xF00007F — DDRCTRL low-priority read CAM 1 register
  [31:24] LPR_XACT_RUN_LENGTH — Transactions serviced once LPR queue goes critical
  [15:0] LPR_MAX_STARVE — DFI clocks that LPR queue can be starved before it goes critical
0x26C DDRCTRL_REGS_PERFWR1 reset 0xF00007F — DDRCTRL write CAM 1 register
  [31:24] W_XACT_RUN_LENGTH — Transactions serviced once the WR queue goes critical
  [15:0] W_MAX_STARVE — DFI clocks that the WR queue can be starved before it goes critical
0x270 DDRCTRL_REGS_SCHED3 reset 0x4040208 — Scheduler control 3 register
  [28:24] RD_PGHIT_NUM_THRESH — Switch to read mode once number of read page-hit request exceeds the threshold set in the register during waiting tless thansub>W2Rless than/sub>.
  [20:16] WR_PGHIT_NUM_THRESH — Switch to write mode once number of write page-hit request exceeds threshold set in this register during waiting delay_switch_write timeout.
  [12:8] WRCAM_HIGHTHRESH — The high threshold used in optimized write CAM fill level.
  [4:0] WRCAM_LOWTHRESH — The low threshold used in optimized write CAM fill level.
0x274 DDRCTRL_REGS_SCHED4 reset 0x8400810 — Scheduler control 4 register
  [31:24] WR_PAGE_EXP_CYCLES — Indicates the number of cycles to keep the bank opened for write direction in read mode when both directions has request to the bank.
  [23:16] RD_PAGE_EXP_CYCLES — Indicates the number of cycles to keep the bank opened for read direction in write mode when both directions has request to the bank.
  [15:8] WR_ACT_IDLE_GAP — Indicates the number of cycles when write direction has no request to start preparing bank for read direction.
  [7:0] RD_ACT_IDLE_GAP — Indicates the number of cycles when read direction has no request to start preparing bank for write direction.
0x300 DDRCTRL_REGS_DBG0 — DDRCTRL debug 0 register
  [7] DIS_MAX_RANK_WR_OPT — Disable optimized max_rank_wr and max_logical_rank_wr
  [6] DIS_MAX_RANK_RD_OPT — Disable optimized max_rank_rd and max_logical_rank_rd.
  [4] DIS_COLLISION_PAGE_OPT — Collision cases are write followed by read to the same address, read followed by write to the same address, or write followed by write to same address with DIS_WC = 1 in this register (where same address comparisons exclude the two address bits representing critical word).
    0=The auto-precharge is disabled for the flushed command in a collision case
  [2] DIS_ACT_BYPASS — Only present in designs supporting activate bypass.
    1=Disable bypass path for high-priority read activates
  [1] DIS_RD_BYPASS — Only present in designs supporting read bypass.
    1=Disable bypass path for high-priority read page hits
  [0] DIS_WC — For debug purpose only.
    1=Disable write combine
0x304 DDRCTRL_REGS_DBG1 — DDRCTRL debug 1 register
  [1] DIS_HIF — This bit is intended to be switched on-the-fly.
    1=DDRCTRL asserts the HIF command signal hif_cmd_stall
  [0] DIS_DQ — All transactions are queued in the CAM.
    1=DDRCTRL does not dequeue any transaction from the CAM
0x308 DDRCTRL_REGS_DBGCAM ro — DDRCTRL CAM debug register
  [29] WR_DATA_PIPELINE_EMPTY — Empty write data pipeline on the DFI interface
  [28] RD_DATA_PIPELINE_EMPTY — Empty read data pipeline on the DFI interface
  [26] DBG_WR_Q_EMPTY — Use-case: When the DDRCTRL enters SR using the low-power entry sequence, the following is expected:
    1=All write command queues and write data buffers inside the DDRC are empty
  [25] DBG_RD_Q_EMPTY — Use-case: When the DDRCTRL enters SR using the low-power entry sequence, the following is expected:
    1=All read command queues and read data buffers inside DDRC are empty
  [24] DBG_STALL — Stall (for debug purpose only)
  [21:16] DBG_W_Q_DEPTH — Write queue depth (for debug purpose only)
  [13:8] DBG_LPR_Q_DEPTH — Low-priority read queue depth (for debug purpose only)
  [5:0] DBG_HPR_Q_DEPTH — High-priority read queue depth (for debug purpose only)
0x30C DDRCTRL_REGS_DBGCMD — DDRCTRL command debug register
  [5] CTRLUPD — dfi_ctrlupd_req to the PHY
    1=The DDRCTRL issues a dfi_ctrlupd_req to the PHY
  [4] ZQ_CALIB_SHORT — ZQCS/MPC command to the SDRAM
    1=The DDRCTRL issues a ZQCS (ZQ calibration short)/MPC (ZQ calibration) command
  [1] RANK1_REFRESH — Refresh to rank 1
    1=The DDRCTRL issues a refresh to rank 1
  [0] RANK0_REFRESH — Refresh to rank 0
    1=The DDRCTRL issues a refresh to rank 0
0x310 DDRCTRL_REGS_DBGSTAT ro — DDRCTRL status debug register
  [5] CTRLUPD_BUSY — CTRLUPD operation
    0=The device can initiate a CTRLUPD operation; 1=No CTRLUPD operation has been initiated yet in the DDRCTRL
  [4] ZQ_CALIB_SHORT_BUSY — ZQCS operation
    0=The device can initiate a ZQCS operation; 1=No ZQCS operation has been initiated yet in the DDRCTRL
  [1] RANK1_REFRESH_BUSY — rank1_refresh operation
    0=The device can initiate a rank1_refresh operation; 1=No rank1_refresh operation has been stored yet in the DDRCTRL
  [0] RANK0_REFRESH_BUSY — rank0_refresh operation
    0=The device can initiate a rank0_refresh operation; 1=No rank0_refresh operation has been stored yet in the DDRCTRL
0x320 DDRCTRL_REGS_SWCTL reset 0x1 — DDRCTRL software programming control enable register
  [0] SW_DONE — Enable quasi-dynamic register programming outside reset
    0=Quasi-dynamic programming enabled
0x324 DDRCTRL_REGS_SWSTAT ro reset 0x1 — DDRCTRL software programming control status register
  [0] SW_DONE_ACK — Register programming done
0x328 DDRCTRL_REGS_SWCTLSTATIC — DDRCTRL statics write enable register
  [0] SW_STATIC_UNLOCK — Enables static register programming outside reset
    1=Static register programming enabled
0x36C DDRCTRL_REGS_POISONCFG reset 0x110011 — DDRCTRL AXI poison configuration register
  [24] RD_POISON_INTR_CLR — Interrupt clear for read transaction poisoning
  [20] RD_POISON_INTR_EN — Interrupts for read transaction poisoning enable
    1=Enable interrupts for read transaction poisoning
  [16] RD_POISON_SLVERR_EN — SLVERR response for read transaction poisoning enable
    1=Enable SLVERR response for read transaction poisoning
  [8] WR_POISON_INTR_CLR — Interrupt clear for write transaction poisoning
  [4] WR_POISON_INTR_EN — Interrupts for write transaction poisoning enable
    1=Enable interrupts for write transaction poisoning
  [0] WR_POISON_SLVERR_EN — SLVERR response for write transaction poisoning enable
    1=Enable SLVERR response for write transaction poisoning
0x370 DDRCTRL_REGS_POISONSTAT ro — DDRCTRL AXI poison status register
  [17] RD_POISON_INTR_1 — Read transaction poisoning error interrupt for port 1
  [16] RD_POISON_INTR_0 — Read transaction poisoning error interrupt for port 0
  [1] WR_POISON_INTR_1 — Write transaction poisoning error interrupt for port 1
  [0] WR_POISON_INTR_0 — Write transaction poisoning error interrupt for port 0
0x3F0 DDRCTRL_REGS_DERATESTAT ro — DDRCTRL temperature derate status register
  [0] DERATE_TEMP_LIMIT_INTR — Derate temperature interrupt
0x3FC DDRCTRL_MP_PSTAT ro — DDRCTRL port status register
  [17] WR_PORT_BUSY_1 — Indicates if there are outstanding writes for AXI port 1.
  [16] WR_PORT_BUSY_0 — Indicates if there are outstanding writes for AXI port 0.
  [1] RD_PORT_BUSY_1 — Indicates if there are outstanding reads for AXI port 1.
  [0] RD_PORT_BUSY_0 — Indicates if there are outstanding reads for AXI port 0.
0x400 DDRCTRL_MP_PCCFG — DDRCTRL port common configuration register
  [8] BL_EXP_MODE — Burst length expansion mode
    0=(default value) XPI expands every AXI burst into multiple HIF commands, using; 1=The XPI uses half of the memory burst length as a unit
  [4] PAGEMATCH_LIMIT — Page match four limit
    1=Limit to four the number of consecutive same page DDRC transactions that can be granted by the port arbiter, when the page match feature is enabled; 0=No limit imposed on number of consecutive same page DDRC transactions
  [0] GO2CRITICAL_EN — Note: Programming mode: Static.
    1=enabled (Set co_gs_go2critical_wr and co_gs_go2critical_lpr/co_gs_go2critical_hpr signals going to DDRC based on urgent input (awurgent, arurgent) coming from AXI master.); 0=disabled (co_gs_go2critical_wr and co_gs_go2critical_lpr/co_gs_go2critical_hpr signals at DDRC are driven to 0.)
0x404 DDRCTRL_MP_PCFGR_0 — DDRCTRL port 0 configuration read register
  [23:20] RRB_LOCK_THRESHOLD — Specifies the RRB lock threshold in configurations that disable read data interleaving.
  [14] RD_PORT_PAGEMATCH_EN — Page match feature enable
    1=Enable the page match feature
  [13] RD_PORT_URGENT_EN — AXI urgent sideband signal (arurgent) enable
    1=Enables arurgent
  [12] RD_PORT_AGING_EN — Aging function for the read channel enable
    1=Enable the aging function for the read channel of the port
  [9:0] RD_PORT_PRIORITY — Initial load value of read aging counters
0x408 DDRCTRL_MP_PCFGW_0 reset 0x4000 — DDRCTRL port 0 configuration write register
  [14] WR_PORT_PAGEMATCH_EN — Page match feature enable
    1=Enable the page match feature
  [13] WR_PORT_URGENT_EN — AXI urgent sideband signal (awurgent) enable
    1=Enable awurgent
  [12] WR_PORT_AGING_EN — Aging function enable for the write channel
    1=Enable the aging function for the write channel of the port
  [9:0] WR_PORT_PRIORITY — Initial load value of write aging counters
0x490 DDRCTRL_MP_PCTRL_0 — DDRCTRL port 0 control register
  [0] PORT_EN — Enable the AXI port x.
0x494 DDRCTRL_MP_PCFGQOS0_0 — DDRCTRL port 0 read QoS configuration 0 register
  [21:20] RQOS_MAP_REGION1 — Traffic class of region 1
    0=LPR; 1=VPR
  [17:16] RQOS_MAP_REGION0 — Traffic class of region 0
    1=VPR
  [3:0] RQOS_MAP_LEVEL1 — Separation level1 that gives the end of region 0 mapping
0x498 DDRCTRL_MP_PCFGQOS1_0 — DDRCTRL port 0 read QoS configuration 1 register
  [26:16] RQOS_MAP_TIMEOUTR — Timeout value for transactions mapped to red address queue
  [10:0] RQOS_MAP_TIMEOUTB — Timeout value for transactions mapped to blue address queue
0x49C DDRCTRL_MP_PCFGWQOS0_0 reset 0xE00 — DDRCTRL port 0 write QoS configuration 0 register
  [25:24] WQOS_MAP_REGION2 — Traffic class of region 2
    0=NPW; 1=VPW
  [21:20] WQOS_MAP_REGION1 — Traffic class of region 1
    0=NPW; 1=VPW
  [17:16] WQOS_MAP_REGION0 — Traffic class of region 0
    1=VPW
  [11:8] WQOS_MAP_LEVEL2 — Separation level2 that indicates the end of region 1 mapping
  [3:0] WQOS_MAP_LEVEL1 — Separation level indicating the end of region 0 mapping
0x4A0 DDRCTRL_MP_PCFGWQOS1_0 — DDRCTRL port 0 write QoS configuration 1 register
  [26:16] WQOS_MAP_TIMEOUT2 — Timeout value for write transactions in region 2
  [10:0] WQOS_MAP_TIMEOUT1 — Timeout value for write transactions in region 0 and 1
0x4B4 DDRCTRL_MP_PCFGR_1 — DDRCTRL port 1 configuration read register
  fields as DDRCTRL_MP_PCFGR_0
0x4B8 DDRCTRL_MP_PCFGW_1 reset 0x4000 — DDRCTRL port 1 configuration write register
  fields as DDRCTRL_MP_PCFGW_0
0x540 DDRCTRL_MP_PCTRL_1 — DDRCTRL port 1 control register
  [0] PORT_EN — Enable the AXI port x.
0x544 DDRCTRL_MP_PCFGQOS0_1 — DDRCTRL port 1 read QoS configuration 0 register
  fields as DDRCTRL_MP_PCFGQOS0_0
0x548 DDRCTRL_MP_PCFGQOS1_1 — DDRCTRL port 1 read QoS configuration 1 register
  fields as DDRCTRL_MP_PCFGQOS1_0
0x54C DDRCTRL_MP_PCFGWQOS0_1 reset 0xE00 — DDRCTRL port 1 write QoS configuration 0 register
  fields as DDRCTRL_MP_PCFGWQOS0_0
0x550 DDRCTRL_MP_PCFGWQOS1_1 — DDRCTRL port 1 write QoS configuration 1 register
  fields as DDRCTRL_MP_PCFGWQOS1_0
0xFF0 DDRCTRL_MP_DDRCTRL_VER_NUMBER ro reset 0x3339312A — DDRCTRL version number register
  [31:0] VER_NUMBER — Device version number
0xFF4 DDRCTRL_MP_DDRCTRL_VER_TYPE ro reset 0x67612A2A — DDRCTRL version type register
  [31:0] VER_TYPE — Device version type value
